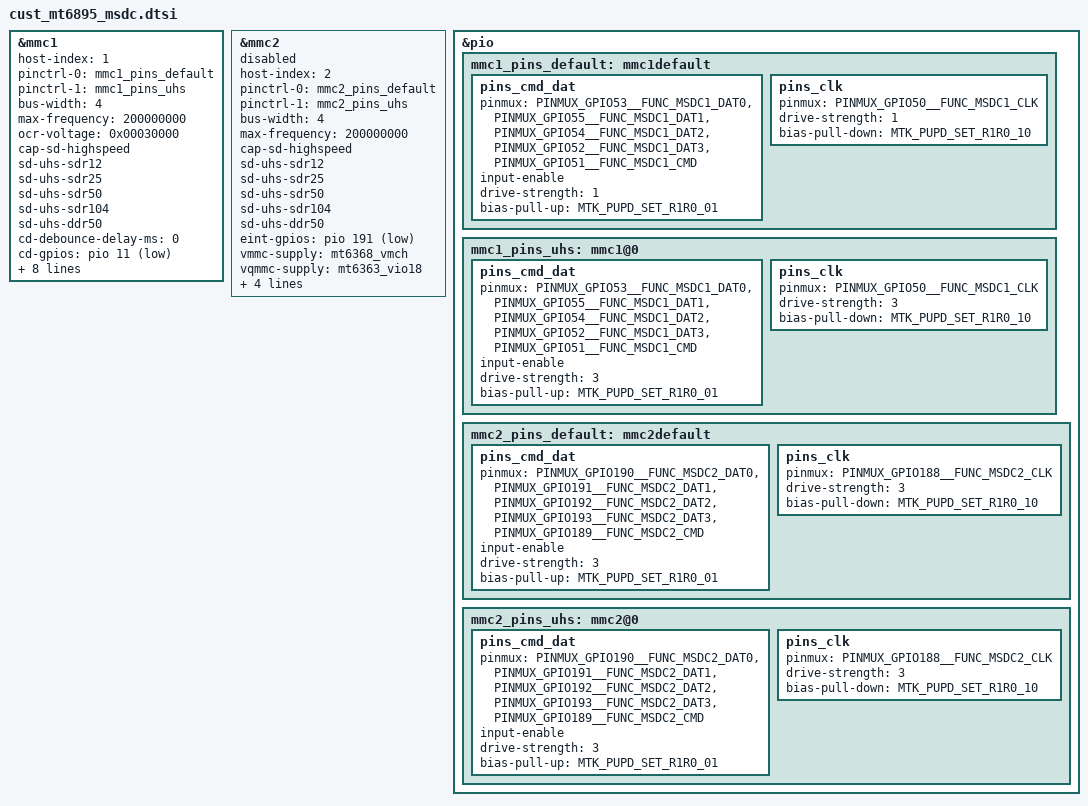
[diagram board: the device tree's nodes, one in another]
// SPDX-License-Identifier: GPL-2.0
/*
 * Copyright (c) 2020 MediaTek Inc.
 */
/********************************************
 * MT6895 MSDC DTSI File
 ********************************************/
#include <dt-bindings/gpio/gpio.h>

&mmc1 {
	host-index = <1>;
	status = "okay";
	pinctrl-names = "default", "state_uhs";
	pinctrl-0 = <&mmc1_pins_default>;
	pinctrl-1 = <&mmc1_pins_uhs>;
	bus-width = <4>;
	max-frequency = <200000000>;
	ocr-voltage = <0x00030000>;
	cap-sd-highspeed;
	sd-uhs-sdr12;
	sd-uhs-sdr25;
	sd-uhs-sdr50;
	sd-uhs-sdr104;
	sd-uhs-ddr50;
	cd-debounce-delay-ms = <0>;
	cd-gpios = <&pio 11 GPIO_ACTIVE_LOW>;
	vmmc-supply = <&mt6368_vmch_eint_high>;
	vqmmc-supply = <&mt6368_vmc>;
	no-mmc;
	no-sdio;
	mediatek,mmc-qos;
	interconnects = <&dvfsrc MT6873_MASTER_UFS &dvfsrc MT6873_SLAVE_DDR_EMI>;
	interconnect-names = "msdc-perf-bw";
	required-opps = <&dvfsrc_freq_opp3>;
};

&mmc2 {
	host-index = <2>;
	status = "disabled";
	pinctrl-names = "default", "state_uhs";
	pinctrl-0 = <&mmc2_pins_default>;
	pinctrl-1 = <&mmc2_pins_uhs>;
	bus-width = <4>;
	max-frequency = <200000000>;
	cap-sd-highspeed;
	sd-uhs-sdr12;
	sd-uhs-sdr25;
	sd-uhs-sdr50;
	sd-uhs-sdr104;
	sd-uhs-ddr50;
	eint-gpios = <&pio 191 GPIO_ACTIVE_LOW>;
	vmmc-supply = <&mt6368_vmch>;
	vqmmc-supply = <&mt6363_vio18>;
	no-mmc;
	no-sd;
	cap-sdio-irq;
	non-removable;
};

&pio {
	mmc1_pins_default: mmc1default {
		pins_cmd_dat {
			pinmux = <PINMUX_GPIO53__FUNC_MSDC1_DAT0>,
				<PINMUX_GPIO55__FUNC_MSDC1_DAT1>,
				<PINMUX_GPIO54__FUNC_MSDC1_DAT2>,
				<PINMUX_GPIO52__FUNC_MSDC1_DAT3>,
				<PINMUX_GPIO51__FUNC_MSDC1_CMD>;
			input-enable;
			drive-strength = <1>;
			bias-pull-up = <MTK_PUPD_SET_R1R0_01>;
		};
		pins_clk {
			pinmux = <PINMUX_GPIO50__FUNC_MSDC1_CLK>;
			drive-strength = <1>;
			bias-pull-down = <MTK_PUPD_SET_R1R0_10>;
		};
	};

	mmc1_pins_uhs: mmc1@0{
		pins_cmd_dat {
			pinmux = <PINMUX_GPIO53__FUNC_MSDC1_DAT0>,
				<PINMUX_GPIO55__FUNC_MSDC1_DAT1>,
				<PINMUX_GPIO54__FUNC_MSDC1_DAT2>,
				<PINMUX_GPIO52__FUNC_MSDC1_DAT3>,
				<PINMUX_GPIO51__FUNC_MSDC1_CMD>;
			input-enable;
			drive-strength = <3>;
			bias-pull-up = <MTK_PUPD_SET_R1R0_01>;
		};
		pins_clk {
			pinmux = <PINMUX_GPIO50__FUNC_MSDC1_CLK>;
			drive-strength = <3>;
			bias-pull-down = <MTK_PUPD_SET_R1R0_10>;
		};
	};

	mmc2_pins_default: mmc2default {
		pins_cmd_dat {
			pinmux = <PINMUX_GPIO190__FUNC_MSDC2_DAT0>,
				<PINMUX_GPIO191__FUNC_MSDC2_DAT1>,
				<PINMUX_GPIO192__FUNC_MSDC2_DAT2>,
				<PINMUX_GPIO193__FUNC_MSDC2_DAT3>,
				<PINMUX_GPIO189__FUNC_MSDC2_CMD>;
			input-enable;
			drive-strength = <3>;
			bias-pull-up = <MTK_PUPD_SET_R1R0_01>;
		};
		pins_clk {
			pinmux = <PINMUX_GPIO188__FUNC_MSDC2_CLK>;
			drive-strength = <3>;
			bias-pull-down = <MTK_PUPD_SET_R1R0_10>;
		};
	};

	mmc2_pins_uhs: mmc2@0{
		pins_cmd_dat {
			pinmux = <PINMUX_GPIO190__FUNC_MSDC2_DAT0>,
				<PINMUX_GPIO191__FUNC_MSDC2_DAT1>,
				<PINMUX_GPIO192__FUNC_MSDC2_DAT2>,
				<PINMUX_GPIO193__FUNC_MSDC2_DAT3>,
				<PINMUX_GPIO189__FUNC_MSDC2_CMD>;
			input-enable;
			drive-strength = <3>;
			bias-pull-up = <MTK_PUPD_SET_R1R0_01>;
		};
		pins_clk {
			pinmux = <PINMUX_GPIO188__FUNC_MSDC2_CLK>;
			drive-strength = <3>;
			bias-pull-down = <MTK_PUPD_SET_R1R0_10>;
		};
	};
};
